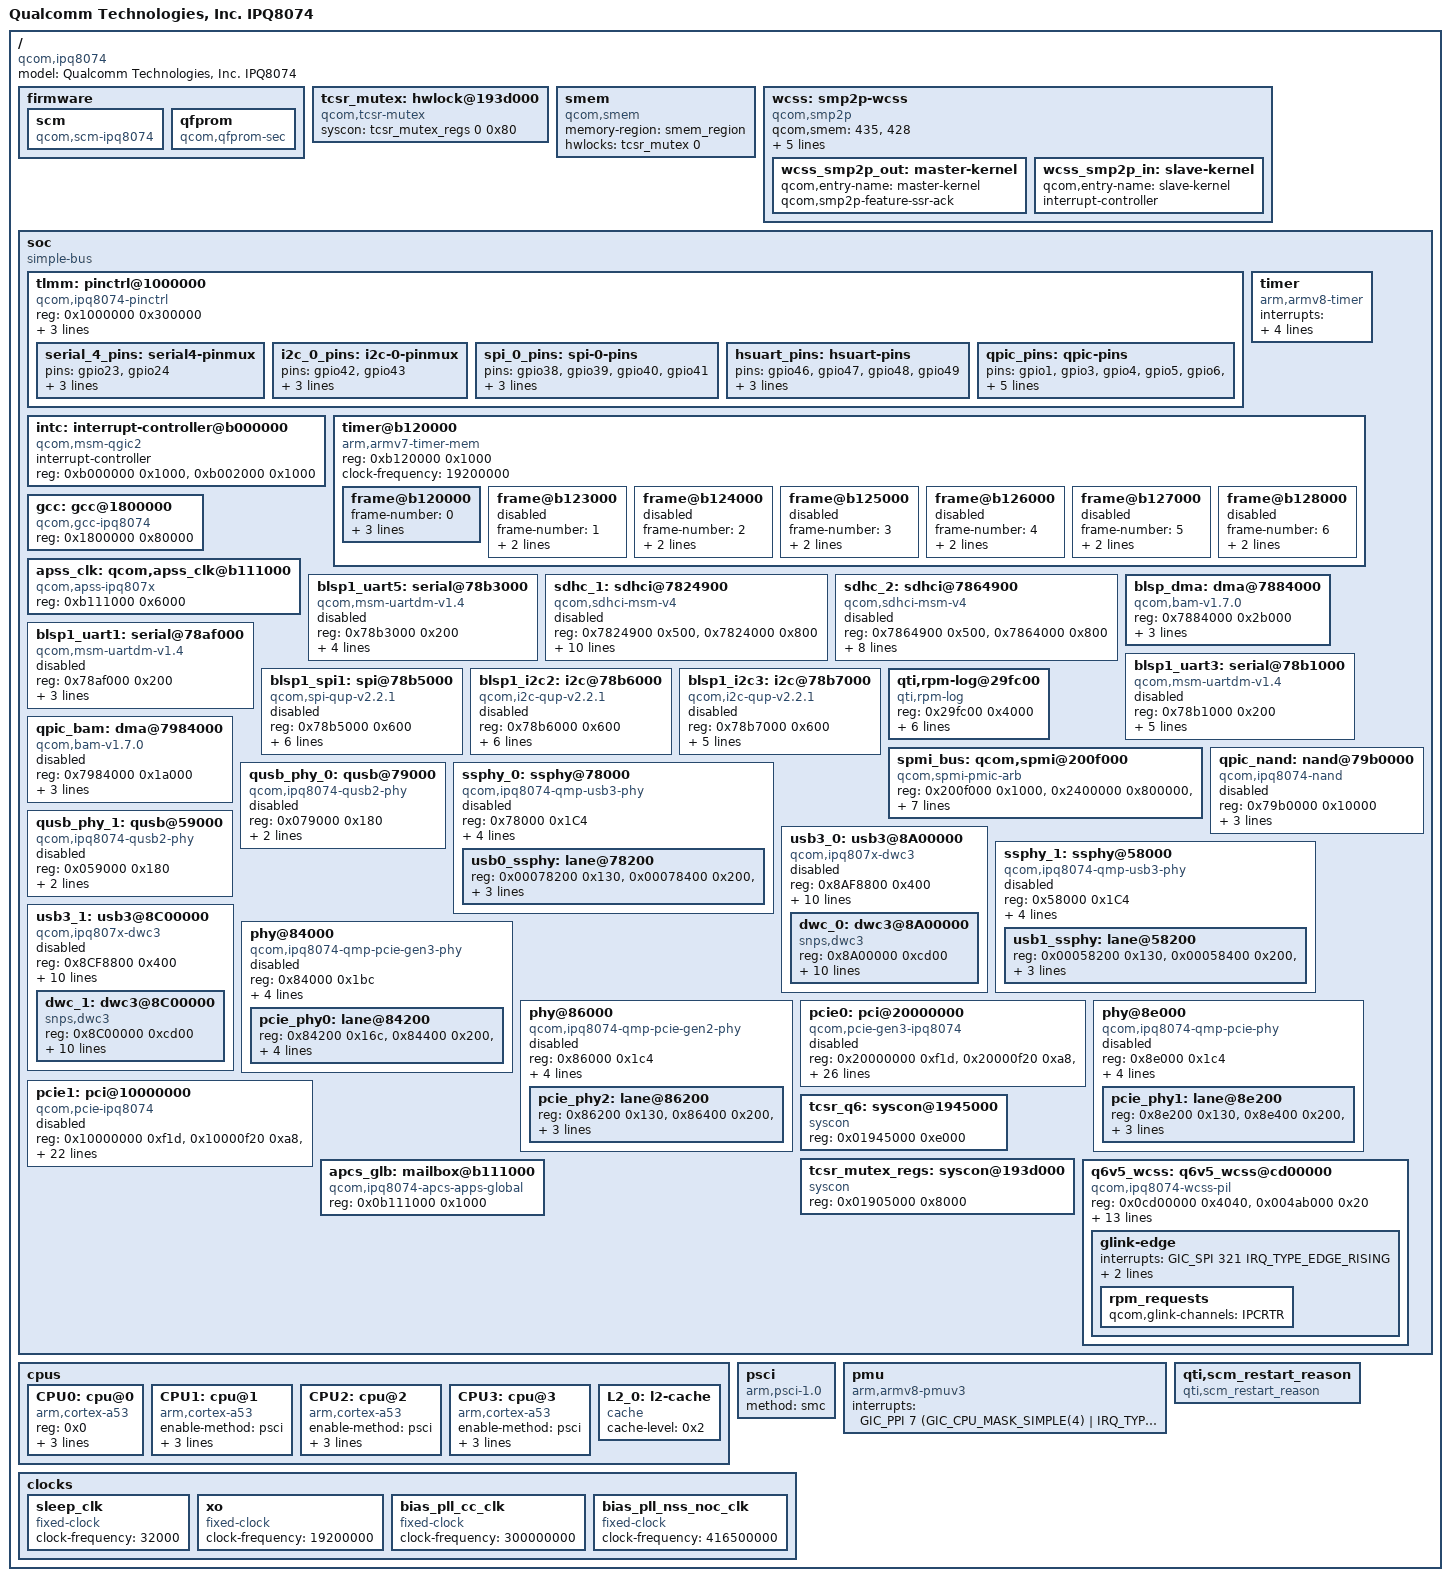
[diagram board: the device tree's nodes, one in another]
// SPDX-License-Identifier: GPL-2.0-only
/*
 * Copyright (c) 2017, The Linux Foundation. All rights reserved.
 */

#include <dt-bindings/interrupt-controller/arm-gic.h>
#include <dt-bindings/clock/qcom,gcc-ipq8074.h>
#include <dt-bindings/clock/qca,apss-ipq8074.h>
#include <dt-bindings/gpio/gpio.h>
#include "ipq8074-memory.dtsi"

/ {
	model = "Qualcomm Technologies, Inc. IPQ8074";
	compatible = "qcom,ipq8074";

	firmware {
		scm {
			compatible = "qcom,scm-ipq8074", "qcom,scm";
		};

		qfprom {
			compatible = "qcom,qfprom-sec";
		};
	};

	tcsr_mutex: hwlock@193d000 {
		compatible = "qcom,tcsr-mutex";
		syscon = <&tcsr_mutex_regs 0 0x80>;
		#hwlock-cells = <1>;
	};

	smem {
		compatible = "qcom,smem";
		memory-region = <&smem_region>;
		hwlocks = <&tcsr_mutex 0>;
	};

	wcss: smp2p-wcss {
		compatible = "qcom,smp2p";
		qcom,smem = <435>, <428>;

		interrupt-parent = <&intc>;
		interrupts = <0 322 1>;

		mboxes = <&apcs_glb 9>;

		qcom,local-pid = <0>;
		qcom,remote-pid = <1>;

		wcss_smp2p_out: master-kernel {
			qcom,entry-name = "master-kernel";
			qcom,smp2p-feature-ssr-ack;
			#qcom,smem-state-cells = <1>;
		};

		wcss_smp2p_in: slave-kernel {
			qcom,entry-name = "slave-kernel";

			interrupt-controller;
			#interrupt-cells = <2>;
		};
	};

	soc: soc {
		#address-cells = <0x1>;
		#size-cells = <0x1>;
		ranges = <0 0 0 0xffffffff>;
		compatible = "simple-bus";

		tlmm: pinctrl@1000000 {
			compatible = "qcom,ipq8074-pinctrl";
			reg = <0x1000000 0x300000>;
			interrupts = <GIC_SPI 208 IRQ_TYPE_LEVEL_HIGH>;
			gpio-controller;
			#gpio-cells = <0x2>;
			interrupt-controller;
			#interrupt-cells = <0x2>;

			serial_4_pins: serial4-pinmux {
				pins = "gpio23", "gpio24";
				function = "blsp4_uart1";
				drive-strength = <8>;
				bias-disable;
			};

			i2c_0_pins: i2c-0-pinmux {
				pins = "gpio42", "gpio43";
				function = "blsp1_i2c";
				drive-strength = <8>;
				bias-disable;
			};

			spi_0_pins: spi-0-pins {
				pins = "gpio38", "gpio39", "gpio40", "gpio41";
				function = "blsp0_spi";
				drive-strength = <8>;
				bias-disable;
			};

			hsuart_pins: hsuart-pins {
				pins = "gpio46", "gpio47", "gpio48", "gpio49";
				function = "blsp2_uart";
				drive-strength = <8>;
				bias-disable;
			};

			qpic_pins: qpic-pins {
				pins = "gpio1", "gpio3", "gpio4",
				       "gpio5", "gpio6", "gpio7",
				       "gpio8", "gpio10", "gpio11",
				       "gpio12", "gpio13", "gpio14",
				       "gpio15", "gpio16", "gpio17";
				function = "qpic";
				drive-strength = <8>;
				bias-disable;
			};
		};

		intc: interrupt-controller@b000000 {
			compatible = "qcom,msm-qgic2";
			interrupt-controller;
			#interrupt-cells = <0x3>;
			reg = <0xb000000 0x1000>, <0xb002000 0x1000>;
		};

		timer {
			compatible = "arm,armv8-timer";
			interrupts = <GIC_PPI 2 (GIC_CPU_MASK_SIMPLE(4) | IRQ_TYPE_LEVEL_LOW)>,
				     <GIC_PPI 3 (GIC_CPU_MASK_SIMPLE(4) | IRQ_TYPE_LEVEL_LOW)>,
				     <GIC_PPI 4 (GIC_CPU_MASK_SIMPLE(4) | IRQ_TYPE_LEVEL_LOW)>,
				     <GIC_PPI 1 (GIC_CPU_MASK_SIMPLE(4) | IRQ_TYPE_LEVEL_LOW)>;
		};

		timer@b120000 {
			#address-cells = <1>;
			#size-cells = <1>;
			ranges;
			compatible = "arm,armv7-timer-mem";
			reg = <0xb120000 0x1000>;
			clock-frequency = <19200000>;

			frame@b120000 {
				frame-number = <0>;
				interrupts = <GIC_SPI 8 IRQ_TYPE_LEVEL_HIGH>,
					     <GIC_SPI 7 IRQ_TYPE_LEVEL_HIGH>;
				reg = <0xb121000 0x1000>,
				      <0xb122000 0x1000>;
			};

			frame@b123000 {
				frame-number = <1>;
				interrupts = <GIC_SPI 9 IRQ_TYPE_LEVEL_HIGH>;
				reg = <0xb123000 0x1000>;
				status = "disabled";
			};

			frame@b124000 {
				frame-number = <2>;
				interrupts = <GIC_SPI 10 IRQ_TYPE_LEVEL_HIGH>;
				reg = <0xb124000 0x1000>;
				status = "disabled";
			};

			frame@b125000 {
				frame-number = <3>;
				interrupts = <GIC_SPI 11 IRQ_TYPE_LEVEL_HIGH>;
				reg = <0xb125000 0x1000>;
				status = "disabled";
			};

			frame@b126000 {
				frame-number = <4>;
				interrupts = <GIC_SPI 12 IRQ_TYPE_LEVEL_HIGH>;
				reg = <0xb126000 0x1000>;
				status = "disabled";
			};

			frame@b127000 {
				frame-number = <5>;
				interrupts = <GIC_SPI 13 IRQ_TYPE_LEVEL_HIGH>;
				reg = <0xb127000 0x1000>;
				status = "disabled";
			};

			frame@b128000 {
				frame-number = <6>;
				interrupts = <GIC_SPI 14 IRQ_TYPE_LEVEL_HIGH>;
				reg = <0xb128000 0x1000>;
				status = "disabled";
			};
		};

		gcc: gcc@1800000 {
			compatible = "qcom,gcc-ipq8074";
			reg = <0x1800000 0x80000>;
			#clock-cells = <0x1>;
			#reset-cells = <0x1>;
		};

		apss_clk: qcom,apss_clk@b111000 {
			compatible = "qcom,apss-ipq807x";
			reg = <0xb111000 0x6000>;
			#clock-cells = <0x1>;
			#reset-cells = <1>;
		};

		blsp1_uart5: serial@78b3000 {
			compatible = "qcom,msm-uartdm-v1.4", "qcom,msm-uartdm";
			reg = <0x78b3000 0x200>;
			interrupts = <GIC_SPI 308 IRQ_TYPE_LEVEL_HIGH>;
			clocks = <&gcc GCC_BLSP1_UART5_APPS_CLK>,
				 <&gcc GCC_BLSP1_AHB_CLK>;
			clock-names = "core", "iface";
			pinctrl-0 = <&serial_4_pins>;
			pinctrl-names = "default";
			status = "disabled";
		};

		sdhc_1: sdhci@7824900 {
			compatible = "qcom,sdhci-msm-v4";
			reg = <0x7824900 0x500>, <0x7824000 0x800>;
			reg-names = "hc_mem", "core_mem";

			interrupts = <GIC_SPI 123 IRQ_TYPE_LEVEL_HIGH>,
					<GIC_SPI 138 IRQ_TYPE_LEVEL_HIGH>;
			interrupt-names = "hc_irq", "pwr_irq";

			clocks = <&xo>,
				<&gcc GCC_SDCC1_AHB_CLK>,
				<&gcc GCC_SDCC1_APPS_CLK>;
			clock-names = "xo", "iface", "core";
			max-frequency = <384000000>;
			mmc-ddr-1_8v;
			mmc-hs200-1_8v;
			mmc-hs400-1_8v;
			bus-width = <8>;
			non-removable;

			status = "disabled";
		};

		sdhc_2: sdhci@7864900 {
			compatible = "qcom,sdhci-msm-v4";
			reg = <0x7864900 0x500>, <0x7864000 0x800>;
			reg-names = "hc_mem", "core_mem";

			interrupts = <GIC_SPI 125 IRQ_TYPE_LEVEL_HIGH>,
					<GIC_SPI 221 IRQ_TYPE_LEVEL_HIGH>;
			interrupt-names = "hc_irq", "pwr_irq";

			clocks = <&xo>,
				<&gcc GCC_SDCC2_AHB_CLK>,
				<&gcc GCC_SDCC2_APPS_CLK>;
			clock-names = "xo", "iface", "core";
			max-frequency = <192000000>;
			mmc-ddr-1_8v;
			mmc-hs200-1_8v;
			bus-width = <4>;

			status = "disabled";
		};

		blsp_dma: dma@7884000 {
			compatible = "qcom,bam-v1.7.0";
			reg = <0x7884000 0x2b000>;
			interrupts = <GIC_SPI 238 IRQ_TYPE_LEVEL_HIGH>;
			clocks = <&gcc GCC_BLSP1_AHB_CLK>;
			clock-names = "bam_clk";
			#dma-cells = <1>;
			qcom,ee = <0>;
		};

		blsp1_uart1: serial@78af000 {
			compatible = "qcom,msm-uartdm-v1.4", "qcom,msm-uartdm";
			reg = <0x78af000 0x200>;
			interrupts = <GIC_SPI 107 IRQ_TYPE_LEVEL_HIGH>;
			clocks = <&gcc GCC_BLSP1_UART1_APPS_CLK>,
				 <&gcc GCC_BLSP1_AHB_CLK>;
			clock-names = "core", "iface";
			status = "disabled";
		};

		blsp1_uart3: serial@78b1000 {
			compatible = "qcom,msm-uartdm-v1.4", "qcom,msm-uartdm";
			reg = <0x78b1000 0x200>;
			interrupts = <GIC_SPI 306 IRQ_TYPE_LEVEL_HIGH>;
			clocks = <&gcc GCC_BLSP1_UART3_APPS_CLK>,
				<&gcc GCC_BLSP1_AHB_CLK>;
			clock-names = "core", "iface";
			dmas = <&blsp_dma 4>,
				<&blsp_dma 5>;
			dma-names = "tx", "rx";
			pinctrl-0 = <&hsuart_pins>;
			pinctrl-names = "default";
			status = "disabled";
		};

		blsp1_spi1: spi@78b5000 {
			compatible = "qcom,spi-qup-v2.2.1";
			#address-cells = <1>;
			#size-cells = <0>;
			reg = <0x78b5000 0x600>;
			interrupts = <GIC_SPI 95 IRQ_TYPE_LEVEL_HIGH>;
			spi-max-frequency = <50000000>;
			clocks = <&gcc GCC_BLSP1_QUP1_SPI_APPS_CLK>,
				<&gcc GCC_BLSP1_AHB_CLK>;
			clock-names = "core", "iface";
			dmas = <&blsp_dma 12>, <&blsp_dma 13>;
			dma-names = "tx", "rx";
			pinctrl-0 = <&spi_0_pins>;
			pinctrl-names = "default";
			status = "disabled";
		};

		blsp1_i2c2: i2c@78b6000 {
			compatible = "qcom,i2c-qup-v2.2.1";
			#address-cells = <1>;
			#size-cells = <0>;
			reg = <0x78b6000 0x600>;
			interrupts = <GIC_SPI 96 IRQ_TYPE_LEVEL_HIGH>;
			clocks = <&gcc GCC_BLSP1_AHB_CLK>,
				<&gcc GCC_BLSP1_QUP2_I2C_APPS_CLK>;
			clock-names = "iface", "core";
			clock-frequency = <400000>;
			dmas = <&blsp_dma 15>, <&blsp_dma 14>;
			dma-names = "rx", "tx";
			pinctrl-0 = <&i2c_0_pins>;
			pinctrl-names = "default";
			status = "disabled";
		};

		blsp1_i2c3: i2c@78b7000 {
			compatible = "qcom,i2c-qup-v2.2.1";
			#address-cells = <1>;
			#size-cells = <0>;
			reg = <0x78b7000 0x600>;
			interrupts = <GIC_SPI 97 IRQ_TYPE_LEVEL_HIGH>;
			clocks = <&gcc GCC_BLSP1_AHB_CLK>,
				<&gcc GCC_BLSP1_QUP3_I2C_APPS_CLK>;
			clock-names = "iface", "core";
			clock-frequency = <100000>;
			dmas = <&blsp_dma 17>, <&blsp_dma 16>;
			dma-names = "rx", "tx";
			status = "disabled";
		};

		qti,rpm-log@29fc00 {
			compatible = "qti,rpm-log";
			reg = <0x29fc00 0x4000>;
			qti,rpm-addr-phys = <0x200000>;
			qti,offset-version = <4>;
			qti,offset-page-buffer-addr = <36>;
			qti,offset-log-len = <40>;
			qti,offset-log-len-mask = <44>;
			qti,offset-page-indices = <56>;
		};

		spmi_bus: qcom,spmi@200f000 {
			compatible = "qcom,spmi-pmic-arb";
			reg = <0x200f000 0x1000>,
				<0x2400000 0x800000>,
				<0x2c00000 0x800000>,
				<0x3800000 0x200000>,
				<0x200a000 0x000700>;
			reg-names = "core", "chnls", "obsrvr", "intr", "cnfg";
			interrupts = <GIC_SPI 190 IRQ_TYPE_LEVEL_HIGH>;
			interrupt-names = "periph_irq";
			qcom,ee = <0>;
			qcom,channel = <0>;
			#address-cells = <2>;
			#size-cells = <0>;
			interrupt-controller;
			#interrupt-cells = <4>;
			cell-index = <0>;
		};

		qpic_bam: dma@7984000 {
			compatible = "qcom,bam-v1.7.0";
			reg = <0x7984000 0x1a000>;
			interrupts = <GIC_SPI 146 IRQ_TYPE_LEVEL_HIGH>;
			clocks = <&gcc GCC_QPIC_AHB_CLK>;
			clock-names = "bam_clk";
			#dma-cells = <1>;
			qcom,ee = <0>;
			status = "disabled";
		};

		qpic_nand: nand@79b0000 {
			compatible = "qcom,ipq8074-nand";
			reg = <0x79b0000 0x10000>;
			#address-cells = <1>;
			#size-cells = <0>;
			clocks = <&gcc GCC_QPIC_CLK>,
				 <&gcc GCC_QPIC_AHB_CLK>;
			clock-names = "core", "aon";

			dmas = <&qpic_bam 0>,
			       <&qpic_bam 1>,
			       <&qpic_bam 2>;
			dma-names = "tx", "rx", "cmd";
			pinctrl-0 = <&qpic_pins>;
			pinctrl-names = "default";
			status = "disabled";
		};

		qusb_phy_0: qusb@79000 {
		    compatible = "qcom,ipq8074-qusb2-phy";
		    reg = <0x079000 0x180>;
		    status = "disabled";
		    #phy-cells = <0>;

		    clocks = <&gcc GCC_USB0_PHY_CFG_AHB_CLK>,
			     <&xo>;
		    clock-names = "cfg_ahb", "ref";

		    resets = <&gcc GCC_QUSB2_0_PHY_BCR>;
		};

		ssphy_0: ssphy@78000 {
			compatible = "qcom,ipq8074-qmp-usb3-phy";
			reg = <0x78000 0x1C4>;
			status = "disabled";
			#clock-cells = <1>;
			#address-cells = <1>;
			#size-cells = <1>;
			ranges;

			clocks = <&gcc GCC_USB0_AUX_CLK>,
				 <&gcc GCC_USB0_PHY_CFG_AHB_CLK>;
			clock-names = "aux", "cfg_ahb";

			resets =  <&gcc GCC_USB0_PHY_BCR>,
				 <&gcc GCC_USB3PHY_0_PHY_BCR>;
			reset-names = "phy","common";

			usb0_ssphy: lane@78200 {
				reg = <0x00078200 0x130>,	/* Tx */
				      <0x00078400 0x200>,	/* Rx */
				      <0x00078800 0x1F8>,	/* PCS  */
				      <0x00078600 0x044>;	/* PCS misc */
				#phy-cells = <0>;
				clocks = <&gcc GCC_USB0_PIPE_CLK>;
				clock-names = "pipe0";
				clock-output-names = "gcc_usb0_pipe_clk_src";
			};
		};

		usb3_0: usb3@8A00000 {
			compatible = "qcom,ipq807x-dwc3", "qcom,dwc3";
			reg = <0x8AF8800 0x400>;
			status = "disabled";
			#address-cells = <1>;
			#size-cells = <1>;
			ranges;

			clocks = <&gcc GCC_SYS_NOC_USB0_AXI_CLK>,
				<&gcc GCC_USB0_MASTER_CLK>,
				<&gcc GCC_USB0_SLEEP_CLK>,
				<&gcc GCC_USB0_MOCK_UTMI_CLK>;
			clock-names = "sys_noc_axi",
				"master",
				"sleep",
				"mock_utmi";

			assigned-clocks = <&gcc GCC_SYS_NOC_USB0_AXI_CLK>,
					  <&gcc GCC_USB0_MASTER_CLK>,
					  <&gcc GCC_USB0_MOCK_UTMI_CLK>;
			assigned-clock-rates = <133330000>,
					       <133330000>,
					       <20000000>;

			resets = <&gcc GCC_USB0_BCR>;

			dwc_0: dwc3@8A00000 {
				compatible = "snps,dwc3";
				reg = <0x8A00000 0xcd00>;
				interrupts = <GIC_SPI 140 IRQ_TYPE_LEVEL_HIGH>;
				phys = <&qusb_phy_0>, <&usb0_ssphy>;
				phy-names = "usb2-phy", "usb3-phy";
				tx-fifo-resize;
				snps,dis_ep_cache_eviction;
				snps,is-utmi-l1-suspend;
				snps,hird-threshold = /bits/ 8 <0x0>;
				snps,dis_u2_susphy_quirk;
				snps,dis_u3_susphy_quirk;
				snps,quirk-ref-clock-period = <0x32>;
				dr_mode = "host";
			};
		};


		qusb_phy_1: qusb@59000 {
		    compatible = "qcom,ipq8074-qusb2-phy";
		    reg = <0x059000 0x180>;
		    status = "disabled";
		    #phy-cells = <0>;

		    clocks = <&gcc GCC_USB1_PHY_CFG_AHB_CLK>,
			     <&xo>;
		    clock-names = "cfg_ahb", "ref";

		    resets = <&gcc GCC_QUSB2_1_PHY_BCR>;
		};

		ssphy_1: ssphy@58000 {
			compatible = "qcom,ipq8074-qmp-usb3-phy";
			reg = <0x58000 0x1C4>;
			status = "disabled";
			#clock-cells = <1>;
			#address-cells = <1>;
			#size-cells = <1>;
			ranges;

			clocks = <&gcc GCC_USB1_AUX_CLK>,
				 <&gcc GCC_USB1_PHY_CFG_AHB_CLK>;
			clock-names = "aux", "cfg_ahb";

			resets =  <&gcc GCC_USB1_PHY_BCR>,
				 <&gcc GCC_USB3PHY_1_PHY_BCR>;
			reset-names = "phy","common";

			usb1_ssphy: lane@58200 {
				reg = <0x00058200 0x130>,	/* Tx */
				      <0x00058400 0x200>,	/* Rx */
				      <0x00058800 0x1F8>,	/* PCS  */
				      <0x00058600 0x044>;	/* PCS misc */
				#phy-cells = <0>;
				clocks = <&gcc GCC_USB1_PIPE_CLK>;
				clock-names = "pipe0";
				clock-output-names = "gcc_usb1_pipe_clk_src";
			};
		};

		usb3_1: usb3@8C00000 {
			compatible = "qcom,ipq807x-dwc3", "qcom,dwc3";
			reg = <0x8CF8800 0x400>;
			status = "disabled";
			#address-cells = <1>;
			#size-cells = <1>;
			ranges;

			clocks = <&gcc GCC_SYS_NOC_USB1_AXI_CLK>,
				<&gcc GCC_USB1_MASTER_CLK>,
				<&gcc GCC_USB1_SLEEP_CLK>,
				<&gcc GCC_USB1_MOCK_UTMI_CLK>;
			clock-names = "sys_noc_axi",
				"master",
				"sleep",
				"mock_utmi";

			assigned-clocks = <&gcc GCC_SYS_NOC_USB1_AXI_CLK>,
					  <&gcc GCC_USB1_MASTER_CLK>,
					  <&gcc GCC_USB1_MOCK_UTMI_CLK>;
			assigned-clock-rates = <133330000>,
					       <133330000>,
					       <20000000>;

			resets = <&gcc GCC_USB1_BCR>;

			dwc_1: dwc3@8C00000 {
				compatible = "snps,dwc3";
				reg = <0x8C00000 0xcd00>;
				interrupts = <GIC_SPI 99 IRQ_TYPE_LEVEL_HIGH>;
				phys = <&qusb_phy_1>, <&usb1_ssphy>;
				phy-names = "usb2-phy", "usb3-phy";
				tx-fifo-resize;
				snps,dis_ep_cache_eviction;
				snps,is-utmi-l1-suspend;
				snps,hird-threshold = /bits/ 8 <0x0>;
				snps,dis_u2_susphy_quirk;
				snps,dis_u3_susphy_quirk;
				snps,quirk-ref-clock-period = <0x32>;
				dr_mode = "host";
			};
		};

		phy@84000 {
			compatible = "qcom,ipq8074-qmp-pcie-gen3-phy";
			reg = <0x84000 0x1bc>; /* Serdes PLL */
			status = "disabled";
			#address-cells = <1>;
			#size-cells = <1>;
			ranges;

			clocks = <&gcc GCC_PCIE0_AUX_CLK>,
				<&gcc GCC_PCIE0_AHB_CLK>;
			clock-names = "aux", "cfg_ahb";

			resets = <&gcc GCC_PCIE0_PHY_BCR>,
				<&gcc GCC_PCIE0PHY_PHY_BCR>;
			reset-names = "phy",
				      "common";

			pcie_phy0: lane@84200 {
				reg = <0x84200 0x16c>, /* Serdes Tx */
				      <0x84400 0x200>, /* Serdes Rx */
				      <0x84800 0x4f4>; /* PCS: Lane0, COM, PCIE */
				#phy-cells = <0>;

				clocks = <&gcc GCC_PCIE0_PIPE_CLK>;
				clock-names = "pipe0";
				clock-output-names = "gcc_pcie0_pipe_clk_src";
				#clock-cells = <0>;
				gen3 = <1>;
			};
		};

		phy@86000 {
			compatible = "qcom,ipq8074-qmp-pcie-gen2-phy";
			reg = <0x86000 0x1c4>; /* Serdes PLL */
			status = "disabled";
			#address-cells = <1>;
			#size-cells = <1>;
			ranges;

			clocks = <&gcc GCC_PCIE0_AUX_CLK>,
				<&gcc GCC_PCIE0_AHB_CLK>;
			clock-names = "aux", "cfg_ahb";

			resets = <&gcc GCC_PCIE0_PHY_BCR>,
				<&gcc GCC_PCIE0PHY_PHY_BCR>;
			reset-names = "phy",
				      "common";

			pcie_phy2: lane@86200 {
				reg = <0x86200 0x130>, /* Serdes Tx */
				      <0x86400 0x200>, /* Serdes Rx */
				      <0x86800 0x1f8>; /* PCS: Lane0, COM, PCIE */
				#phy-cells = <0>;

				clocks = <&gcc GCC_PCIE0_PIPE_CLK>;
				clock-names = "pipe0";
				clock-output-names = "gcc_pcie0_pipe_clk_src";
				#clock-cells = <0>;
			};
		};

		pcie0: pci@20000000 {
			compatible = "qcom,pcie-gen3-ipq8074";
			reg = <0x20000000 0xf1d>,
			      <0x20000f20 0xa8>,
			      <0x20001000 0x1000>,
			      <0x80000 0x2000>,
			      <0x20100000 0x1000>;
			reg-names = "dbi", "elbi", "atu", "parf", "config";

			device_type = "pci";
			linux,pci-domain = <0>;
			bus-range = <0x00 0xff>;
			num-lanes = <1>;
			#address-cells = <3>;
			#size-cells = <2>;

			phys = <&pcie_phy0>, <&pcie_phy2>;
			phy-names = "pciephy-gen3", "pciephy-gen2";

			ranges = <0x81000000 0 0x20200000 0x20200000
				  0 0x10000>, /* downstream I/O */
				 <0x82000000 0 0x20220000 0x20220000
				  0 0xfde0000>; /* non-prefetchable memory */

			interrupts = <GIC_SPI 52 IRQ_TYPE_LEVEL_HIGH>;
			interrupt-names = "msi";
			#interrupt-cells = <1>;
			interrupt-map-mask = <0 0 0 0x7>;
			interrupt-map = <0 0 0 1 &intc 0 75
					 IRQ_TYPE_LEVEL_HIGH>, /* int_a */
					<0 0 0 2 &intc 0 78
					 IRQ_TYPE_LEVEL_HIGH>, /* int_b */
					<0 0 0 3 &intc 0 79
					 IRQ_TYPE_LEVEL_HIGH>, /* int_c */
					<0 0 0 4 &intc 0 83
					 IRQ_TYPE_LEVEL_HIGH>; /* int_d */

			clocks = <&gcc GCC_SYS_NOC_PCIE0_AXI_CLK>,
				 <&gcc GCC_PCIE0_AXI_M_CLK>,
				 <&gcc GCC_PCIE0_AXI_S_CLK>,
				 <&gcc GCC_PCIE0_AXI_S_BRIDGE_CLK>,
				 <&gcc PCIE0_RCHNG_CLK>;
			clock-names = "iface",
				      "axi_m",
				      "axi_s",
				      "axi_bridge",
				      "rchng";

			resets = <&gcc GCC_PCIE0_PIPE_ARES>,
				 <&gcc GCC_PCIE0_SLEEP_ARES>,
				 <&gcc GCC_PCIE0_CORE_STICKY_ARES>,
				 <&gcc GCC_PCIE0_AXI_MASTER_ARES>,
				 <&gcc GCC_PCIE0_AXI_SLAVE_ARES>,
				 <&gcc GCC_PCIE0_AHB_ARES>,
				 <&gcc GCC_PCIE0_AXI_MASTER_STICKY_ARES>,
				 <&gcc GCC_PCIE0_AXI_SLAVE_STICKY_ARES>;
			reset-names = "pipe",
				      "sleep",
				      "sticky",
				      "axi_m",
				      "axi_s",
				      "ahb",
				      "axi_m_sticky",
				      "axi_s_sticky";

			status = "disabled";
		};

		phy@8e000 {
			compatible = "qcom,ipq8074-qmp-pcie-phy";
			reg = <0x8e000 0x1c4>; /* Serdes PLL */
			status = "disabled";
			#address-cells = <1>;
			#size-cells = <1>;
			ranges;

			clocks = <&gcc GCC_PCIE1_AUX_CLK>,
				<&gcc GCC_PCIE1_AHB_CLK>;
			clock-names = "aux", "cfg_ahb";

			resets = <&gcc GCC_PCIE1_PHY_BCR>,
				<&gcc GCC_PCIE1PHY_PHY_BCR>;
			reset-names = "phy",
				      "common";

			pcie_phy1: lane@8e200 {
				reg = <0x8e200 0x130>, /* Serdes Tx */
				      <0x8e400 0x200>, /* Serdes Rx */
				      <0x8e800 0x1f8>; /* PCS: Lane0, COM, PCIE */
				#phy-cells = <0>;

				clocks = <&gcc GCC_PCIE1_PIPE_CLK>;
				clock-names = "pipe0";
				clock-output-names = "gcc_pcie1_pipe_clk_src";
				#clock-cells = <0>;
			};
		};

		pcie1: pci@10000000 {
			compatible = "qcom,pcie-ipq8074";
			reg = <0x10000000 0xf1d>,
			      <0x10000f20 0xa8>,
			      <0x88000 0x2000>,
			      <0x10100000 0x1000>;
			reg-names = "dbi", "elbi", "parf", "config";

			device_type = "pci";
			linux,pci-domain = <1>;
			bus-range = <0x00 0xff>;
			num-lanes = <1>;
			#address-cells = <3>;
			#size-cells = <2>;

			phys = <&pcie_phy1>;
			phy-names = "pciephy";

			ranges = <0x81000000 0 0x10200000 0x10200000
				  0 0x10000>,   /* downstream I/O */
				 <0x82000000 0 0x10220000 0x10220000
				  0 0xfde0000>; /* non-prefetchable memory */

			interrupts = <GIC_SPI 85 IRQ_TYPE_LEVEL_HIGH>;
			interrupt-names = "msi";
			#interrupt-cells = <1>;
			interrupt-map-mask = <0 0 0 0x7>;
			interrupt-map = <0 0 0 1 &intc 0 142
					 IRQ_TYPE_LEVEL_HIGH>, /* int_a */
					<0 0 0 2 &intc 0 143
					 IRQ_TYPE_LEVEL_HIGH>, /* int_b */
					<0 0 0 3 &intc 0 144
					 IRQ_TYPE_LEVEL_HIGH>, /* int_c */
					<0 0 0 4 &intc 0 145
					 IRQ_TYPE_LEVEL_HIGH>; /* int_d */

			clocks = <&gcc GCC_SYS_NOC_PCIE1_AXI_CLK>,
				 <&gcc GCC_PCIE1_AXI_M_CLK>,
				 <&gcc GCC_PCIE1_AXI_S_CLK>;
			clock-names = "iface",
				      "axi_m",
				      "axi_s";

			resets = <&gcc GCC_PCIE1_PIPE_ARES>,
				 <&gcc GCC_PCIE1_SLEEP_ARES>,
				 <&gcc GCC_PCIE1_CORE_STICKY_ARES>,
				 <&gcc GCC_PCIE1_AXI_MASTER_ARES>,
				 <&gcc GCC_PCIE1_AXI_SLAVE_ARES>,
				 <&gcc GCC_PCIE1_AHB_ARES>,
				 <&gcc GCC_PCIE1_AXI_MASTER_STICKY_ARES>;
			reset-names = "pipe",
				      "sleep",
				      "sticky",
				      "axi_m",
				      "axi_s",
				      "ahb",
				      "axi_m_sticky";

			status = "disabled";
		};

		tcsr_q6: syscon@1945000 {
			compatible = "syscon";
			reg = <0x01945000 0xe000>;
		};

		tcsr_mutex_regs: syscon@193d000 {
			compatible = "syscon";
			reg = <0x01905000 0x8000>;
		};

		apcs_glb: mailbox@b111000 {
			compatible = "qcom,ipq8074-apcs-apps-global";
			reg = <0x0b111000 0x1000>;

			#mbox-cells = <1>;
		};

		q6v5_wcss: q6v5_wcss@cd00000 {
			compatible = "qcom,ipq8074-wcss-pil";
			reg = <0x0cd00000 0x4040>,
			      <0x004ab000 0x20>;
			reg-names = "qdsp6",
				    "rmb";
			qca,auto-restart;
			qca,extended-intc;
			interrupts-extended = <&intc 0 325 1>,
					      <&wcss_smp2p_in 0 0>,
					      <&wcss_smp2p_in 1 0>,
					      <&wcss_smp2p_in 2 0>,
					      <&wcss_smp2p_in 3 0>;
			interrupt-names = "wdog",
					  "fatal",
					  "ready",
					  "handover",
					  "stop-ack";

			resets = <&gcc GCC_WCSSAON_RESET>,
				 <&gcc GCC_WCSS_BCR>,
				 <&gcc GCC_WCSS_Q6_BCR>;

			reset-names = "wcss_aon_reset",
				      "wcss_reset",
				      "wcss_q6_reset";

			clocks = <&gcc GCC_PRNG_AHB_CLK>;
			clock-names = "prng";

			qcom,halt-regs = <&tcsr_q6 0xa000 0xd000 0x0>;

			qcom,smem-states = <&wcss_smp2p_out 0>,
					   <&wcss_smp2p_out 1>;
			qcom,smem-state-names = "shutdown",
						"stop";

			memory-region = <&q6_region>;

			glink-edge {
				interrupts = <GIC_SPI 321 IRQ_TYPE_EDGE_RISING>;
				qcom,remote-pid = <1>;
				mboxes = <&apcs_glb 8>;

				rpm_requests {
					qcom,glink-channels = "IPCRTR";
				};
			};
		};
	};

	cpus {
		#address-cells = <0x1>;
		#size-cells = <0x0>;

		CPU0: cpu@0 {
			device_type = "cpu";
			compatible = "arm,cortex-a53";
			reg = <0x0>;
			clocks = <&apss_clk APCS_ALIAS0_CORE_CLK>;
			clock-names = "cpu";
			next-level-cache = <&L2_0>;
			enable-method = "psci";
		};

		CPU1: cpu@1 {
			device_type = "cpu";
			compatible = "arm,cortex-a53";
			enable-method = "psci";
			reg = <0x1>;
			clocks = <&apss_clk APCS_ALIAS0_CORE_CLK>;
			clock-names = "cpu";
			next-level-cache = <&L2_0>;
		};

		CPU2: cpu@2 {
			device_type = "cpu";
			compatible = "arm,cortex-a53";
			enable-method = "psci";
			reg = <0x2>;
			clocks = <&apss_clk APCS_ALIAS0_CORE_CLK>;
			clock-names = "cpu";
			next-level-cache = <&L2_0>;
		};

		CPU3: cpu@3 {
			device_type = "cpu";
			compatible = "arm,cortex-a53";
			enable-method = "psci";
			reg = <0x3>;
			clocks = <&apss_clk APCS_ALIAS0_CORE_CLK>;
			clock-names = "cpu";
			next-level-cache = <&L2_0>;
		};

		L2_0: l2-cache {
			compatible = "cache";
			cache-level = <0x2>;
		};
	};

	psci {
		compatible = "arm,psci-1.0";
		method = "smc";
	};

	pmu {
		compatible = "arm,armv8-pmuv3";
		interrupts = <GIC_PPI 7 (GIC_CPU_MASK_SIMPLE(4) | IRQ_TYPE_LEVEL_HIGH)>;
	};

	clocks {
		sleep_clk: sleep_clk {
			compatible = "fixed-clock";
			clock-frequency = <32000>;
			#clock-cells = <0>;
		};

		xo: xo {
			compatible = "fixed-clock";
			clock-frequency = <19200000>;
			#clock-cells = <0>;
		};

		bias_pll_cc_clk {
			compatible = "fixed-clock";
			clock-frequency = <300000000>;
			#clock-cells = <0>;
		};

		bias_pll_nss_noc_clk {
			compatible = "fixed-clock";
			clock-frequency = <416500000>;
			#clock-cells = <0>;
		};
	};

	qti,scm_restart_reason {
		compatible = "qti,scm_restart_reason";
	};
};
